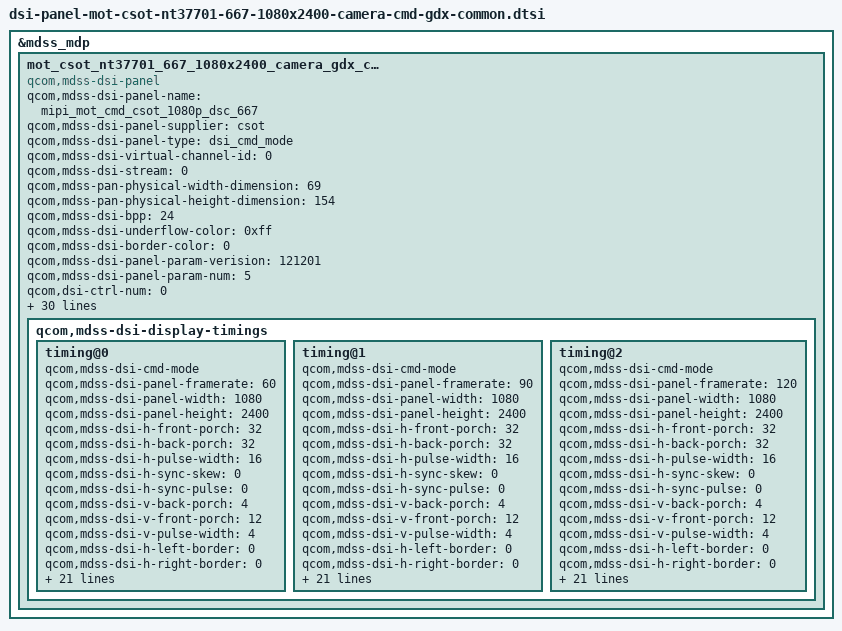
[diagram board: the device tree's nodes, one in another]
/* Copyright (c) 2019-2020, The Linux Foundation. All rights reserved.
 *
 * This program is free software; you can redistribute it and/or modify
 * it under the terms of the GNU General Public License version 2 and
 * only version 2 as published by the Free Software Foundation.
 *
 * This program is distributed in the hope that it will be useful,
 * but WITHOUT ANY WARRANTY; without even the implied warranty of
 * MERCHANTABILITY or FITNESS FOR A PARTICULAR PURPOSE.  See the
 * GNU General Public License for more details.
 */
&mdss_mdp {
mot_csot_nt37701_667_1080x2400_camera_gdx_cmd: qcom,mdss_dsi_mot_csot_nt37701_667_1080x2400_cam_gdx_cmd {
compatible = "qcom,mdss-dsi-panel";
qcom,mdss-dsi-panel-name = "mipi_mot_cmd_csot_1080p_dsc_667";
qcom,mdss-dsi-panel-supplier = "csot";
qcom,mdss-dsi-panel-type = "dsi_cmd_mode";
qcom,mdss-dsi-virtual-channel-id = <0>;
qcom,mdss-dsi-stream = <0>;
qcom,mdss-pan-physical-width-dimension = <69>;
qcom,mdss-pan-physical-height-dimension = <154>;
qcom,mdss-dsi-bpp = <24>;
qcom,mdss-dsi-underflow-color = <0xff>;
qcom,mdss-dsi-border-color = <0>;
qcom,mdss-dsi-panel-param-verision = <121201>;
qcom,mdss-dsi-panel-param-num = <5>;

qcom,dsi-ctrl-num = <0>;
qcom,dsi-phy-num = <0>;

qcom,mdss-dsi-traffic-mode = "burst_mode";
qcom,mdss-dsi-bllp-eof-power-mode;
qcom,mdss-dsi-bllp-power-mode;
qcom,mdss-dsi-lane-0-state;
qcom,mdss-dsi-lane-1-state;
qcom,mdss-dsi-lane-2-state;
qcom,mdss-dsi-lane-3-state;

qcom,mdss-dsi-dma-trigger = "trigger_sw";
qcom,mdss-dsi-mdp-trigger = "none";
qcom,mdss-dsi-reset-sequence = <0 11>, <1 1>, <0 1>, <1 11>;
qcom,mdss-dsi-lp11-init;
qcom,mdss-dsi-tx-eot-append;
qcom,mdss-dsi-te-pin-select = <1>;
qcom,mdss-dsi-te-dcs-command = <1>;
qcom,mdss-dsi-te-using-te-pin;

//qcom,bklt-dcs-2bytes-enabled;
qcom,mdss-dsi-bl-min-level = <3>;
qcom,mdss-dsi-bl-max-level = <2047>;
qcom,mdss-dsi-bl-pmic-control-type = "bl_ctrl_dcs";

qcom,mdss-dsi-panel-hdr-enabled;
qcom,mdss-dsi-panel-hdr-color-primaries = <14500 15500 32000
	        17000 15500 30000 8000 3000>;
qcom,mdss-dsi-panel-peak-brightness = <4200000>;

qcom,mdss-dsi-panel-blackness-level = <3230>;

qcom,mdss-dsi-hbm-on-command = [
		39 01 00 00 00 00 03 51 0F FF];
qcom,mdss-dsi-hbm-off-command = [
		39 01 00 00 00 00 03 51 07 FF];


//qcom,mdss-dsi-acl-on-command = [
//		39 01 00 00 00 00 06 F0 55 AA 52 08 00
//		15 00 00 00 00 00 02 B0 0C
//		15 01 00 00 00 00 02 55 05];
//qcom,mdss-dsi-acl-off-command = [
//		15 01 00 00 00 00 02 55 00];

qcom,mdss-dsi-display-timings {
	timing@0{
		qcom,mdss-dsi-cmd-mode;
		qcom,mdss-dsi-panel-framerate = <60>;
		qcom,mdss-dsi-panel-width = <1080>;
		qcom,mdss-dsi-panel-height = <2400>;
		qcom,mdss-dsi-h-front-porch = <32>;
		qcom,mdss-dsi-h-back-porch = <32>;
		qcom,mdss-dsi-h-pulse-width = <16>;
		qcom,mdss-dsi-h-sync-skew = <0>;
		qcom,mdss-dsi-h-sync-pulse = <0>;
		qcom,mdss-dsi-v-back-porch = <4>;
		qcom,mdss-dsi-v-front-porch = <12>;
		qcom,mdss-dsi-v-pulse-width = <4>;
		qcom,mdss-dsi-h-left-border = <0>;
		qcom,mdss-dsi-h-right-border = <0>;
		qcom,mdss-dsi-v-top-border = <0>;
		qcom,mdss-dsi-v-bottom-border = <0>;
		qcom,mdss-dsi-panel-jitter = <0x20 0xa>; /* 90fps +/- 2 */
		qcom,mdss-dsi-timing-switch-command = [
                        39 01 00 00 00 00 06 F0 55 AA 52 08 02
                        15 01 00 00 00 00 02 6F 03
                        15 01 00 00 00 00 02 BF 02
                        15 01 00 00 00 00 02 2F 01
		];

		qcom,mdss-dsi-on-command = [
                        39 01 00 00 00 00 06 F0 55 AA 52 08 00
                        39 01 00 00 00 00 03 C0 4E F3
                        39 01 00 00 00 00 02 6F 02
                        39 01 00 00 00 00 02 C0 21
                        39 01 00 00 00 00 06 F0 55 AA 52 08 04
                        39 01 00 00 00 00 02 C2 14
                        39 01 00 00 00 00 02 B1 03
                        39 01 00 00 00 00 02 B2 40
                        39 01 00 00 00 00 04 B8 0F 00 00
                        39 01 00 00 00 00 02 6F 03
                        39 01 00 00 00 00 04 B8 07 70 00
                        39 01 00 00 00 00 02 6F 01
                        39 01 00 00 00 00 02 C7 FF
                        39 01 00 00 00 00 04 B7 C1 40 04
                        39 01 00 00 00 00 02 6F 0B
                        39 01 00 00 00 00 02 CA FF
                        39 01 00 00 00 00 06 F0 55 AA 52 08 08
                        39 01 00 00 00 00 07 C1 A7 00 3B 81 90 1E
                        39 01 00 00 00 00 02 6F 06
                        39 01 00 00 00 00 08 C1 64 89 A4 BB CF E1 F1
                        39 01 00 00 00 00 10 C2 88 00 00 88 00 00 88 00 00 88 00 00 88 00 00
                        39 01 00 00 00 00 0d C3 88 00 00 88 00 00 88 00 00 88 00 00
                        39 01 00 00 00 00 0c C4 44 00 00 44 00 00 44 00 00 04 00
                        39 01 00 00 00 00 0a C5 88 00 00 88 00 00 88 00 00
                        39 01 00 00 00 00 02 C6 11
                        39 01 00 00 00 00 09 C7 50 50 60 70 70 80 80 80
                        39 01 00 00 00 00 09 C8 50 50 60 70 80 80 A0 A0
                        39 01 00 00 00 00 09 C9 20 20 30 40 50 70 B0 B0
                        39 01 00 00 00 00 0f CA 00 14 27 00 4E 9D 21 3B 74 B8 B0 3E 0F FF
                        39 01 00 00 00 00 0f CB 00 13 25 00 4A 95 21 29 52 A8 42 94 0F FF
                        39 01 00 00 00 00 0f CD 00 0F 1F 00 3D 7A 10 F5 EA CB 5C 69 0F FF
                        39 01 00 00 00 00 10 CE 22 00 00 22 00 00 22 00 00 22 00 00 22 00 00
                        39 01 00 00 00 00 02 6F 0F
                        39 01 00 00 00 00 0D CE 22 00 00 22 00 00 22 00 00 22 00 00
                        39 01 00 00 00 00 02 6F 1B
                        39 01 00 00 00 00 1c CE FF FF FF FF FF FF FF FF FF FF FF FF FF FF FF FF FF FF FF FF FF FF FF FF FF FF FF
                        39 01 00 00 00 00 15 CF FF FF FF FF FF FF FF FF FF 0F FF FF FF FF FF FF FF FF FF FF
                        39 01 00 00 00 00 02 6F 22
                        39 01 00 00 00 00 0a D0 00 00 00 00 00 00 00 00 00
                        39 01 00 00 00 00 03 D2 00 01
                        39 01 00 00 00 00 02 6F 02
                        39 01 00 00 00 00 0a D2 10 00 87 00 2C 00 00 00 00
                        39 01 00 00 00 00 06 F0 55 AA 52 08 08
                        39 01 00 00 00 00 07 C1 A7 00 3B 81 90 1E

                        39 01 00 00 00 00 06 F0 55 AA 52 08 00
                        15 01 00 00 00 00 02 6F 06
                        39 01 00 00 00 00 04 B5 4E 19 50
                        15 01 00 00 00 00 02 6F 0D
                        15 01 00 00 00 00 02 B5 50
                        15 01 00 00 00 00 02 6F 10
                        39 01 00 00 00 00 06 B5 19 19 19 19 19
                        15 01 00 00 00 00 02 99 10
                        15 01 00 00 00 00 02 90 01
                        39 01 00 00 00 00 13 91 AB 28 00 0C C2 00 03 1C 01 7E 00 0F 08 BB 04 3D 10 F0
                        15 01 00 00 00 00 02 03 01
                        05 01 00 00 00 00 01 2C
                        39 01 00 00 00 00 03 51 00 00
                        05 01 00 00 00 00 01 35
                        15 01 00 00 00 00 02 53 20
                        39 01 00 00 00 00 05 2A 00 00 04 37
                        39 01 00 00 00 00 05 2B 00 00 09 5F
                        39 01 00 00 00 00 06 F0 55 AA 52 08 02
                        15 01 00 00 00 00 02 6F 03
                        15 01 00 00 00 00 02 BF 02
                        15 01 00 00 00 00 02 2F 01

			05 01 00 00 6e 00 01 11
			05 01 00 00 00 00 01 29];	/* display on */
		qcom,mdss-dsi-off-command = [
			05 01 00 00 00 00 01 28		/* display_off */
			05 01 00 00 78 00 01 10];	/* enter sleep mode */

		qcom,mdss-dsi-on-command-state = "dsi_lp_mode";
		qcom,mdss-dsi-off-command-state = "dsi_lp_mode";
		qcom,mdss-dsi-timing-switch-command-state =
			"dsi_lp_mode";
		qcom,compression-mode = "dsc";
		/* Why QCOM doesn't use this, even it used 2 encoder
		 * as for that dsi_sw43404_amoled_cmd, for ex */
		/* qcom,mdss-dsc-encoders = <2>; */
		qcom,mdss-dsc-version = <0x11>;
		qcom,mdss-dsc-slice-height = <12>;
		qcom,mdss-dsc-slice-width = <1080>;
		qcom,mdss-dsc-slice-per-pkt = <1>;
		qcom,mdss-dsc-bit-per-component = <10>;
		qcom,mdss-dsc-bit-per-pixel = <8>;
		qcom,mdss-dsc-block-prediction-enable;
	};
	timing@1{
		qcom,mdss-dsi-cmd-mode;
		qcom,mdss-dsi-panel-framerate = <90>;
		qcom,mdss-dsi-panel-width = <1080>;
		qcom,mdss-dsi-panel-height = <2400>;
		qcom,mdss-dsi-h-front-porch = <32>;
		qcom,mdss-dsi-h-back-porch = <32>;
		qcom,mdss-dsi-h-pulse-width = <16>;
		qcom,mdss-dsi-h-sync-skew = <0>;
		qcom,mdss-dsi-h-sync-pulse = <0>;
		qcom,mdss-dsi-v-back-porch = <4>;
		qcom,mdss-dsi-v-front-porch = <12>;
		qcom,mdss-dsi-v-pulse-width = <4>;
		qcom,mdss-dsi-h-left-border = <0>;
		qcom,mdss-dsi-h-right-border = <0>;
		qcom,mdss-dsi-v-top-border = <0>;
		qcom,mdss-dsi-v-bottom-border = <0>;
		qcom,mdss-dsi-panel-jitter = <0x20 0xa>; /* 90fps +/- 2 */
		qcom,mdss-dsi-timing-switch-command = [
                        39 01 00 00 00 00 06 F0 55 AA 52 08 02
                        15 01 00 00 00 00 02 6F 03
                        15 01 00 00 00 00 02 BF 05
                        15 01 00 00 00 00 02 2F 02
		];

		qcom,mdss-dsi-on-command = [
                        39 01 00 00 00 00 06 F0 55 AA 52 08 00
                        39 01 00 00 00 00 03 C0 4E F3
                        39 01 00 00 00 00 02 6F 02
                        39 01 00 00 00 00 02 C0 21
                        39 01 00 00 00 00 06 F0 55 AA 52 08 04
                        39 01 00 00 00 00 02 C2 14
                        39 01 00 00 00 00 02 B1 03
                        39 01 00 00 00 00 02 B2 40
                        39 01 00 00 00 00 04 B8 0F 00 00
                        39 01 00 00 00 00 02 6F 03
                        39 01 00 00 00 00 04 B8 07 70 00
                        39 01 00 00 00 00 02 6F 01
                        39 01 00 00 00 00 02 C7 FF
                        39 01 00 00 00 00 04 B7 C1 40 04
                        39 01 00 00 00 00 02 6F 0B
                        39 01 00 00 00 00 02 CA FF
                        39 01 00 00 00 00 06 F0 55 AA 52 08 08
                        39 01 00 00 00 00 07 C1 A7 00 3B 81 90 1E
                        39 01 00 00 00 00 02 6F 06
                        39 01 00 00 00 00 08 C1 64 89 A4 BB CF E1 F1
                        39 01 00 00 00 00 10 C2 88 00 00 88 00 00 88 00 00 88 00 00 88 00 00
                        39 01 00 00 00 00 0d C3 88 00 00 88 00 00 88 00 00 88 00 00
                        39 01 00 00 00 00 0c C4 44 00 00 44 00 00 44 00 00 04 00
                        39 01 00 00 00 00 0a C5 88 00 00 88 00 00 88 00 00
                        39 01 00 00 00 00 02 C6 11
                        39 01 00 00 00 00 09 C7 50 50 60 70 70 80 80 80
                        39 01 00 00 00 00 09 C8 50 50 60 70 80 80 A0 A0
                        39 01 00 00 00 00 09 C9 20 20 30 40 50 70 B0 B0
                        39 01 00 00 00 00 0f CA 00 14 27 00 4E 9D 21 3B 74 B8 B0 3E 0F FF
                        39 01 00 00 00 00 0f CB 00 13 25 00 4A 95 21 29 52 A8 42 94 0F FF
                        39 01 00 00 00 00 0f CD 00 0F 1F 00 3D 7A 10 F5 EA CB 5C 69 0F FF
                        39 01 00 00 00 00 10 CE 22 00 00 22 00 00 22 00 00 22 00 00 22 00 00
                        39 01 00 00 00 00 02 6F 0F
                        39 01 00 00 00 00 0D CE 22 00 00 22 00 00 22 00 00 22 00 00
                        39 01 00 00 00 00 02 6F 1B
                        39 01 00 00 00 00 1c CE FF FF FF FF FF FF FF FF FF FF FF FF FF FF FF FF FF FF FF FF FF FF FF FF FF FF FF
                        39 01 00 00 00 00 15 CF FF FF FF FF FF FF FF FF FF 0F FF FF FF FF FF FF FF FF FF FF
                        39 01 00 00 00 00 02 6F 22
                        39 01 00 00 00 00 0a D0 00 00 00 00 00 00 00 00 00
                        39 01 00 00 00 00 03 D2 00 01
                        39 01 00 00 00 00 02 6F 02
                        39 01 00 00 00 00 0a D2 10 00 87 00 2C 00 00 00 00
                        39 01 00 00 00 00 06 F0 55 AA 52 08 08
                        39 01 00 00 00 00 07 C1 A7 00 3B 81 90 1E

                        39 01 00 00 00 00 06 F0 55 AA 52 08 00
                        15 01 00 00 00 00 02 6F 06
                        39 01 00 00 00 00 04 B5 4E 19 50
                        15 01 00 00 00 00 02 6F 0D
                        15 01 00 00 00 00 02 B5 50
                        15 01 00 00 00 00 02 6F 10
                        39 01 00 00 00 00 06 B5 19 19 19 19 19
                        15 01 00 00 00 00 02 99 10
                        15 01 00 00 00 00 02 90 01
                        39 01 00 00 00 00 13 91 AB 28 00 0C C2 00 03 1C 01 7E 00 0F 08 BB 04 3D 10 F0
                        15 01 00 00 00 00 02 03 01
                        05 01 00 00 00 00 01 2C
                        39 01 00 00 00 00 03 51 00 00
                        05 01 00 00 00 00 01 35
                        15 01 00 00 00 00 02 53 20
                        39 01 00 00 00 00 05 2A 00 00 04 37
                        39 01 00 00 00 00 05 2B 00 00 09 5F

                        39 01 00 00 00 00 06 F0 55 AA 52 08 02
                        15 01 00 00 00 00 02 6F 03
                        15 01 00 00 00 00 02 BF 05
                        15 01 00 00 00 00 02 2F 02

			05 01 00 00 6e 00 01 11
			05 01 00 00 00 00 01 29];	/* display on */
		qcom,mdss-dsi-off-command = [
			05 01 00 00 00 00 01 28		/* display_off */
			05 01 00 00 78 00 01 10];	/* enter sleep mode */

		qcom,mdss-dsi-on-command-state = "dsi_lp_mode";
		qcom,mdss-dsi-off-command-state = "dsi_lp_mode";
		qcom,mdss-dsi-timing-switch-command-state =
			"dsi_lp_mode";
		qcom,compression-mode = "dsc";
		/* Why QCOM doesn't use this, even it used 2 encoder
		 * as for that dsi_sw43404_amoled_cmd, for ex */
		/* qcom,mdss-dsc-encoders = <2>; */
		qcom,mdss-dsc-version = <0x11>;
		qcom,mdss-dsc-slice-height = <12>;
		qcom,mdss-dsc-slice-width = <1080>;
		qcom,mdss-dsc-slice-per-pkt = <1>;
		qcom,mdss-dsc-bit-per-component = <10>;
		qcom,mdss-dsc-bit-per-pixel = <8>;
		qcom,mdss-dsc-block-prediction-enable;
	};
	timing@2{
		qcom,mdss-dsi-cmd-mode;
		qcom,mdss-dsi-panel-framerate = <120>;
		qcom,mdss-dsi-panel-width = <1080>;
		qcom,mdss-dsi-panel-height = <2400>;
		qcom,mdss-dsi-h-front-porch = <32>;
		qcom,mdss-dsi-h-back-porch = <32>;
		qcom,mdss-dsi-h-pulse-width = <16>;
		qcom,mdss-dsi-h-sync-skew = <0>;
		qcom,mdss-dsi-h-sync-pulse = <0>;
		qcom,mdss-dsi-v-back-porch = <4>;
		qcom,mdss-dsi-v-front-porch = <12>;
		qcom,mdss-dsi-v-pulse-width = <4>;
		qcom,mdss-dsi-h-left-border = <0>;
		qcom,mdss-dsi-h-right-border = <0>;
		qcom,mdss-dsi-v-top-border = <0>;
		qcom,mdss-dsi-v-bottom-border = <0>;
		qcom,mdss-dsi-panel-jitter = <0x20 0xa>; /* 90fps +/- 2 */
		qcom,mdss-dsi-timing-switch-command = [
                        39 01 00 00 00 00 06 F0 55 AA 52 08 02
                        15 01 00 00 00 00 02 6F 03
                        15 01 00 00 00 00 02 BF 03
                        15 01 00 00 00 00 02 2F 03
		];

		qcom,mdss-dsi-on-command = [
                        39 01 00 00 00 00 06 F0 55 AA 52 08 00
                        39 01 00 00 00 00 03 C0 4E F3
                        39 01 00 00 00 00 02 6F 02
                        39 01 00 00 00 00 02 C0 21
                        39 01 00 00 00 00 06 F0 55 AA 52 08 04
                        39 01 00 00 00 00 02 C2 14
                        39 01 00 00 00 00 02 B1 03
                        39 01 00 00 00 00 02 B2 40
                        39 01 00 00 00 00 04 B8 0F 00 00
                        39 01 00 00 00 00 02 6F 03
                        39 01 00 00 00 00 04 B8 07 70 00
                        39 01 00 00 00 00 02 6F 01
                        39 01 00 00 00 00 02 C7 FF
                        39 01 00 00 00 00 04 B7 C1 40 04
                        39 01 00 00 00 00 02 6F 0B
                        39 01 00 00 00 00 02 CA FF
                        39 01 00 00 00 00 06 F0 55 AA 52 08 08
                        39 01 00 00 00 00 07 C1 A7 00 3B 81 90 1E
                        39 01 00 00 00 00 02 6F 06
                        39 01 00 00 00 00 08 C1 64 89 A4 BB CF E1 F1
                        39 01 00 00 00 00 10 C2 88 00 00 88 00 00 88 00 00 88 00 00 88 00 00
                        39 01 00 00 00 00 0d C3 88 00 00 88 00 00 88 00 00 88 00 00
                        39 01 00 00 00 00 0c C4 44 00 00 44 00 00 44 00 00 04 00
                        39 01 00 00 00 00 0a C5 88 00 00 88 00 00 88 00 00
                        39 01 00 00 00 00 02 C6 11
                        39 01 00 00 00 00 09 C7 50 50 60 70 70 80 80 80
                        39 01 00 00 00 00 09 C8 50 50 60 70 80 80 A0 A0
                        39 01 00 00 00 00 09 C9 20 20 30 40 50 70 B0 B0
                        39 01 00 00 00 00 0f CA 00 14 27 00 4E 9D 21 3B 74 B8 B0 3E 0F FF
                        39 01 00 00 00 00 0f CB 00 13 25 00 4A 95 21 29 52 A8 42 94 0F FF
                        39 01 00 00 00 00 0f CD 00 0F 1F 00 3D 7A 10 F5 EA CB 5C 69 0F FF
                        39 01 00 00 00 00 10 CE 22 00 00 22 00 00 22 00 00 22 00 00 22 00 00
                        39 01 00 00 00 00 02 6F 0F
                        39 01 00 00 00 00 0D CE 22 00 00 22 00 00 22 00 00 22 00 00
                        39 01 00 00 00 00 02 6F 1B
                        39 01 00 00 00 00 1c CE FF FF FF FF FF FF FF FF FF FF FF FF FF FF FF FF FF FF FF FF FF FF FF FF FF FF FF
                        39 01 00 00 00 00 15 CF FF FF FF FF FF FF FF FF FF 0F FF FF FF FF FF FF FF FF FF FF
                        39 01 00 00 00 00 02 6F 22
                        39 01 00 00 00 00 0a D0 00 00 00 00 00 00 00 00 00
                        39 01 00 00 00 00 03 D2 00 01
                        39 01 00 00 00 00 02 6F 02
                        39 01 00 00 00 00 0a D2 10 00 87 00 2C 00 00 00 00
                        39 01 00 00 00 00 06 F0 55 AA 52 08 08
                        39 01 00 00 00 00 07 C1 A7 00 3B 81 90 1E

                        39 01 00 00 00 00 06 F0 55 AA 52 08 00
                        15 01 00 00 00 00 02 6F 06
                        39 01 00 00 00 00 04 B5 4E 19 50
                        15 01 00 00 00 00 02 6F 0D
                        15 01 00 00 00 00 02 B5 50
                        15 01 00 00 00 00 02 6F 10
                        39 01 00 00 00 00 06 B5 19 19 19 19 19
                        15 01 00 00 00 00 02 99 10
                        15 01 00 00 00 00 02 90 01
                        39 01 00 00 00 00 13 91 AB 28 00 0C C2 00 03 1C 01 7E 00 0F 08 BB 04 3D 10 F0
                        15 01 00 00 00 00 02 03 01
                        05 01 00 00 00 00 01 2C
                        39 01 00 00 00 00 03 51 00 00
                        05 01 00 00 00 00 01 35
                        15 01 00 00 00 00 02 53 20
                        39 01 00 00 00 00 05 2A 00 00 04 37
                        39 01 00 00 00 00 05 2B 00 00 09 5F

                        39 01 00 00 00 00 06 F0 55 AA 52 08 02
                        15 01 00 00 00 00 02 6F 03
                        15 01 00 00 00 00 02 BF 03
                        15 01 00 00 00 00 02 2F 03

			05 01 00 00 6e 00 01 11
			05 01 00 00 00 00 01 29];	/* display on */
		qcom,mdss-dsi-off-command = [
			05 01 00 00 00 00 01 28		/* display_off */
			05 01 00 00 78 00 01 10];	/* enter sleep mode */

		qcom,mdss-dsi-on-command-state = "dsi_lp_mode";
		qcom,mdss-dsi-off-command-state = "dsi_lp_mode";
		qcom,mdss-dsi-timing-switch-command-state =
			"dsi_lp_mode";
		qcom,compression-mode = "dsc";
		/* Why QCOM doesn't use this, even it used 2 encoder
		 * as for that dsi_sw43404_amoled_cmd, for ex */
		/* qcom,mdss-dsc-encoders = <2>; */
		qcom,mdss-dsc-version = <0x11>;
		qcom,mdss-dsc-slice-height = <12>;
		qcom,mdss-dsc-slice-width = <1080>;
		qcom,mdss-dsc-slice-per-pkt = <1>;
		qcom,mdss-dsc-bit-per-component = <10>;
		qcom,mdss-dsc-bit-per-pixel = <8>;
		qcom,mdss-dsc-block-prediction-enable;
	};

};

};

};
